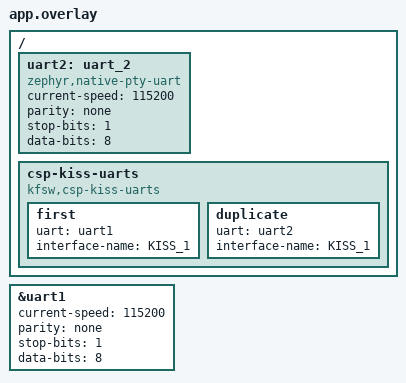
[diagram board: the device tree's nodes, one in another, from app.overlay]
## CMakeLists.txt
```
cmake_minimum_required(VERSION 3.20.0)

get_filename_component(KFSW_WORKSPACE_ROOT
    "${CMAKE_CURRENT_LIST_DIR}/../../../.."
    ABSOLUTE
)

list(APPEND ZEPHYR_EXTRA_MODULES
    "${KFSW_WORKSPACE_ROOT}/kfsw-platform"
    "${KFSW_WORKSPACE_ROOT}/kfsw-comms/third_party/libcsp"
    "${KFSW_WORKSPACE_ROOT}/kfsw-comms"
)

set(CSP_REPRODUCIBLE_BUILDS ON CACHE BOOL "" FORCE)
set(CSP_USE_RDP OFF CACHE BOOL "" FORCE)
set(CSP_USE_HMAC OFF CACHE BOOL "" FORCE)
set(CSP_USE_PROMISC OFF CACHE BOOL "" FORCE)

find_package(Zephyr REQUIRED HINTS $ENV{ZEPHYR_BASE})
project(kfsw_comms_uart_validation_tests LANGUAGES C)

target_sources(app PRIVATE src/main.c)
target_link_libraries(app PRIVATE kfsw::comms)
```

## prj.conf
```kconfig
CONFIG_ZTEST=y
CONFIG_SERIAL=y
CONFIG_HEAP_MEM_POOL_SIZE=4096

CONFIG_KFSW_CSP=y
CONFIG_KFSW_CSP_ADDRESS=7
CONFIG_KFSW_CSP_HOSTNAME="kfsw-uart-validation"
CONFIG_KFSW_CSP_KISS_UART=y
CONFIG_KFSW_CSP_ROUTE_TABLE="0/0 KISS_1"
CONFIG_CSP_UART_RX_THREAD_NUM=2
```

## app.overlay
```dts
&uart1 {
	current-speed = <115200>;
	parity = "none";
	stop-bits = "1";
	data-bits = <8>;
	status = "okay";
};

/ {
	uart2: uart_2 {
		compatible = "zephyr,native-pty-uart";
		current-speed = <115200>;
		parity = "none";
		stop-bits = "1";
		data-bits = <8>;
		status = "okay";
	};

	csp-kiss-uarts {
		compatible = "kfsw,csp-kiss-uarts";
		status = "okay";

		first {
			uart = <&uart1>;
			interface-name = "KISS_1";
		};

		duplicate {
			uart = <&uart2>;
			interface-name = "KISS_1";
		};
	};
};
```

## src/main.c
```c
#include <zephyr/ztest.h>

#include <csp/csp.h>

#include <kfsw/comms/csp.h>

ZTEST(comms_uart_validation, test_duplicate_interface_name_is_rejected)
{
	zassert_equal(kfsw_csp_init(), CSP_ERR_INVAL);
}

ZTEST_SUITE(comms_uart_validation, NULL, NULL, NULL, NULL, NULL);
```
